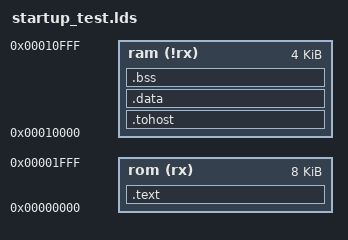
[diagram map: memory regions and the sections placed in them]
/* gp sits 0x800 into .data, as in dhry.lds and coremark.lds, so a benchmark-shaped .bss
   reference lands in gp-relative range and exercises the same startup path. */
MEMORY {
    rom(rx)  : ORIGIN = 0x00000000, LENGTH = 8K
    ram(!rx) : ORIGIN = 0x00010000, LENGTH = 4K
}

SECTIONS {
    .text : {
        *(.text.init);
        *(.text);
        *(.text.*);
        . = ALIGN(4);
    } >rom

    .tohost : {
        *(.tohost);
        . = ALIGN(4);
    } >ram

    .data : {
        __global_pointer$ = . + 0x800;
        *(.rodata);
        *(.rodata.*);
        *(.srodata);
        *(.srodata.*);
        *(.sdata);
        *(.sdata.*);
        *(.data);
        *(.data.*);
        . = ALIGN(4);
    } >ram

    .bss (NOLOAD) : {
        __bss_start = .;
        *(.sbss);
        *(.sbss.*);
        *(.bss);
        *(.bss.*);
        *(COMMON);
        . = ALIGN(4);
        __bss_end = .;
    } >ram

    __stack_top = ORIGIN(ram) + LENGTH(ram);
}
